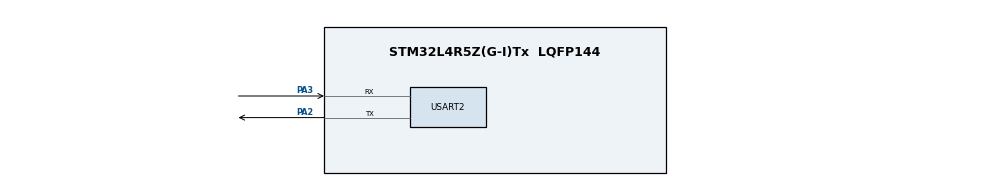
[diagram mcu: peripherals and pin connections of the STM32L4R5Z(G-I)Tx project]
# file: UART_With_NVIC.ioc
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Mcu.Family=STM32L4
Mcu.Name=STM32L4R5Z(G-I)Tx
Mcu.Package=LQFP144
NVIC.PriorityGroup=NVIC_PRIORITYGROUP_4
NVIC.USART2_IRQn=true\:0\:0\:false\:false\:true\:true\:true\:true
PA2.Mode=Asynchronous
PA2.Signal=USART2_TX
PA3.Mode=Asynchronous
PA3.Signal=USART2_RX
ProjectManager.HeapSize=0x200
ProjectManager.StackSize=0x400
ProjectManager.TargetToolchain=MDK-ARM V5.32
RCC.HSE_VALUE=8000000
RCC.HSI48_VALUE=48000000
RCC.HSI_VALUE=16000000
RCC.LSE_VALUE=32768
RCC.MSI_VALUE=4000000
RCC.VCOOutputFreq_Value=32000000
USART2.VirtualMode-Asynchronous=VM_ASYNC
board=custom

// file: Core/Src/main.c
/* USER CODE BEGIN Header */
/**
  ******************************************************************************
  * @file           : main.c
  * @brief          : Main program body
  ******************************************************************************
  * @attention
  *
  * Copyright (c) 2024 STMicroelectronics.
  * All rights reserved.
  *
  * This software is licensed under terms that can be found in the LICENSE file
  * in the root directory of this software component.
  * If no LICENSE file comes with this software, it is provided AS-IS.
  *
  ******************************************************************************
  */
/* USER CODE END Header */
#include "main.h"
#include "string.h"
#include "UART_Learning.h" // Include the new header file

UART_HandleTypeDef huart2;

void Blink_LED2(char LED_Number)
{
  HAL_GPIO_WritePin(GPIOB, GPIO_PIN_7, GPIO_PIN_RESET);
  HAL_Delay(500);
  HAL_GPIO_WritePin(GPIOB, GPIO_PIN_7, GPIO_PIN_SET);
  HAL_Delay(500);
}
/* USER CODE BEGIN PV */
#define BUFFER_SIZE 1024

uint8_t AccumulationBuffer[BUFFER_SIZE];
uint16_t AccumulationIndex = 0;

/* USER CODE END PV */

void SystemClock_Config(void);
static void MX_GPIO_Init(void);
static void MX_USART2_UART_Init(void);
void ProcessUARTData(void); // Declare the new function

int main(void)
{

  /* MCU Configuration--------------------------------------------------------*/

  /* Reset of all peripherals, Initializes the Flash interface and the Systick. */
  HAL_Init();

  /* Configure the system clock */
  SystemClock_Config();

  /* Initialize all configured peripherals */
  MX_GPIO_Init();
  MX_USART2_UART_Init();
  /* USER CODE BEGIN 2 */
  char *initialMessage = "hello vaibhav\r\n";
  HAL_UART_Transmit(&huart2, (uint8_t*)initialMessage, strlen(initialMessage), HAL_MAX_DELAY);
  HAL_UART_Receive_IT(&huart2, (uint8_t *)rxBuffer.buffer, BUFFER_SIZE);
  /* USER CODE END 2 */

  /* Infinite loop */
  /* USER CODE BEGIN WHILE */
  while (1)
  {
		Blink_LED2(1);
    /* Call the new function */
    /* USER CODE END WHILE */
  }
}

void SystemClock_Config(void)
{
  RCC_OscInitTypeDef RCC_OscInitStruct = {0};
  RCC_ClkInitTypeDef RCC_ClkInitStruct = {0};

  /** Configure the main internal regulator output voltage
  */
  if (HAL_PWREx_ControlVoltageScaling(PWR_REGULATOR_VOLTAGE_SCALE1) != HAL_OK)
  {
    Error_Handler();
  }

  /** Initializes the RCC Oscillators according to the specified parameters
  * in the RCC_OscInitTypeDef structure.
  */
  RCC_OscInitStruct.OscillatorType = RCC_OSCILLATORTYPE_MSI;
  RCC_OscInitStruct.MSIState = RCC_MSI_ON;
  RCC_OscInitStruct.MSICalibrationValue = 0;
  RCC_OscInitStruct.MSIClockRange = RCC_MSIRANGE_6;
  RCC_OscInitStruct.PLL.PLLState = RCC_PLL_NONE;
  if (HAL_RCC_OscConfig(&RCC_OscInitStruct) != HAL_OK)
  {
    Error_Handler();
  }

  /** Initializes the CPU, AHB and APB buses clocks
  */
  RCC_ClkInitStruct.ClockType = RCC_CLOCKTYPE_HCLK|RCC_CLOCKTYPE_SYSCLK
                              |RCC_CLOCKTYPE_PCLK1|RCC_CLOCKTYPE_PCLK2;
  RCC_ClkInitStruct.SYSCLKSource = RCC_SYSCLKSOURCE_MSI;
  RCC_ClkInitStruct.AHBCLKDivider = RCC_SYSCLK_DIV1;
  RCC_ClkInitStruct.APB1CLKDivider = RCC_HCLK_DIV1;
  RCC_ClkInitStruct.APB2CLKDivider = RCC_HCLK_DIV1;

  if (HAL_RCC_ClockConfig(&RCC_ClkInitStruct, FLASH_LATENCY_0) != HAL_OK)
  {
    Error_Handler();
  }
}

static void MX_USART2_UART_Init(void)
{
  huart2.Instance = USART2;
  huart2.Init.BaudRate = 300; //9600; //115200;
  huart2.Init.WordLength = UART_WORDLENGTH_8B;
  huart2.Init.StopBits = UART_STOPBITS_1;
  huart2.Init.Parity = UART_PARITY_NONE;
  huart2.Init.Mode = UART_MODE_TX_RX;
  huart2.Init.HwFlowCtl = UART_HWCONTROL_NONE;
  huart2.Init.OverSampling = UART_OVERSAMPLING_16;
  huart2.Init.OneBitSampling = UART_ONE_BIT_SAMPLE_DISABLE;
  huart2.Init.ClockPrescaler = UART_PRESCALER_DIV1;
  huart2.AdvancedInit.AdvFeatureInit = UART_ADVFEATURE_NO_INIT;
  if (HAL_UART_Init(&huart2) != HAL_OK)
  {
    Error_Handler();
  }
  HAL_UART_Receive_IT(&huart2, (uint8_t *)rxBuffer.buffer, 1); // Initialize receive interrupt for 1 byte
}

static void MX_GPIO_Init(void)
{
  /* GPIO Ports Clock Enable */
  __HAL_RCC_GPIOA_CLK_ENABLE();
		GPIO_InitTypeDef GPIO_InitStruct = {0};

  /* GPIO Ports Clock Enable */
  __HAL_RCC_GPIOB_CLK_ENABLE();

	/*Configure GPIO pin Output Level */
  HAL_GPIO_WritePin(GPIOB, GPIO_PIN_7, GPIO_PIN_RESET);

  /*Configure GPIO pin : PB7 */
  GPIO_InitStruct.Pin = GPIO_PIN_7;
  GPIO_InitStruct.Mode = GPIO_MODE_OUTPUT_PP;
  GPIO_InitStruct.Pull = GPIO_NOPULL;
  GPIO_InitStruct.Speed = GPIO_SPEED_FREQ_LOW;
  HAL_GPIO_Init(GPIOB, &GPIO_InitStruct);
}

/* USER CODE BEGIN 4 */

void HAL_UART_RxCpltCallback(UART_HandleTypeDef *huart)
{
    if (huart->Instance == USART2)
		{
        uint8_t data = rxBuffer.buffer[0]; /* Read the received data */
        AccumulationBuffer[AccumulationIndex++] = data; /* Store data in accumulation buffer */

        /* Check if we have received 1024 characters */
        if (AccumulationIndex == BUFFER_SIZE)
				{
            /* Copy accumulated data to transmit buffer */
            for (int i = 0; i < BUFFER_SIZE; i++)
						{
              CyclicBuffer_Write(&txBuffer, AccumulationBuffer[i]);
            }
            AccumulationIndex = 0; /* Reset accumulation index */

            /* Start transmission */
            if (__HAL_UART_GET_FLAG(&huart2, UART_FLAG_TXE))
						{
              uint8_t txData = CyclicBuffer_Read(&txBuffer);
              HAL_UART_Transmit_IT(&huart2, &txData, 1);
            }
        }

        /* Re-enable the receive interrupt for 1 character */
        HAL_UART_Receive_IT(&huart2, (uint8_t *)rxBuffer.buffer, 1);
     }
}

void HAL_UART_TxCpltCallback(UART_HandleTypeDef *huart)
{
    if (huart->Instance == USART2)
		{
      if (txBuffer.head != txBuffer.tail)
			{
        uint8_t data = CyclicBuffer_Read(&txBuffer);
        HAL_UART_Transmit_IT(&huart2, &data, 1); /* Transmit only 1 byte */
      }
    }
}

/* USER CODE END 4 */

void Error_Handler(void)
{
  __disable_irq();
  while (1)
  {
  }
}
